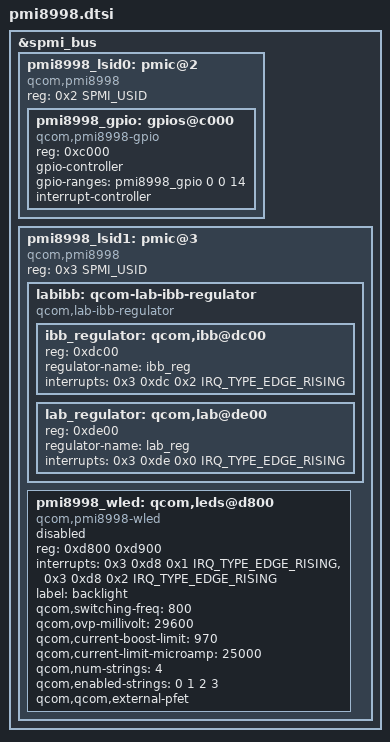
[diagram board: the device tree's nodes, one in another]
// SPDX-License-Identifier: GPL-2.0
#include <dt-bindings/interrupt-controller/irq.h>
#include <dt-bindings/spmi/spmi.h>

&spmi_bus {
	pmi8998_lsid0: pmic@2 {
		compatible = "qcom,pmi8998", "qcom,spmi-pmic";
		reg = <0x2 SPMI_USID>;
		#address-cells = <1>;
		#size-cells = <0>;

		pmi8998_gpio: gpios@c000 {
			compatible = "qcom,pmi8998-gpio", "qcom,spmi-gpio";
			reg = <0xc000>;
			gpio-controller;
			gpio-ranges = <&pmi8998_gpio 0 0 14>;
			#gpio-cells = <2>;
			interrupt-controller;
			#interrupt-cells = <2>;
		};
	};

	pmi8998_lsid1: pmic@3 {
		compatible = "qcom,pmi8998", "qcom,spmi-pmic";
		reg = <0x3 SPMI_USID>;
		#address-cells = <1>;
		#size-cells = <0>;

		labibb: qcom-lab-ibb-regulator {
			compatible = "qcom,lab-ibb-regulator";
			#address-cells = <1>;
			#size-cells = <0>;

			ibb_regulator: qcom,ibb@dc00 {
				reg = <0xdc00>;
				regulator-name = "ibb_reg";

				interrupts = <0x3 0xdc 0x2 IRQ_TYPE_EDGE_RISING>;
				interrupt-names = "ibb-sc-err";
			};

			lab_regulator: qcom,lab@de00 {
				reg = <0xde00>;
				regulator-name = "lab_reg";

				interrupts = <0x3 0xde 0x0 IRQ_TYPE_EDGE_RISING>;
				interrupt-names = "lab-sc-err";
			};
		};

		pmi8998_wled: qcom,leds@d800 {
			compatible = "qcom,pmi8998-wled";
			reg = <0xd800 0xd900>;
			interrupts = <0x3 0xd8 0x1 IRQ_TYPE_EDGE_RISING>,
				     <0x3 0xd8 0x2 IRQ_TYPE_EDGE_RISING>;
			interrupt-names = "ovp-irq", "sc-irq";
			label = "backlight";

			qcom,switching-freq = <800>;
			qcom,ovp-millivolt = <29600>;
			qcom,current-boost-limit = <970>;
			qcom,current-limit-microamp = <25000>;
			qcom,num-strings = <4>;
			qcom,enabled-strings = <0 1 2 3>;
			qcom,qcom,external-pfet;

			status = "disabled";
		};

	};
};
